# AM335x register map
Vendor: Texas Instruments; Series: Sitara AM335x; File version: 1.1
CPU: Cortex-A8 r0p0, little endian
Registers are 32-bit, read-write, reset 0x0 unless marked. A register's access mark holds for its fields unless they carry their own. Offsets are from the block's base; [hi:lo] are bit positions; {n}, {i} and the like mark numbered series.

## PRM_MPU — Power Reset Module - MPU
Base 0x44E00E00
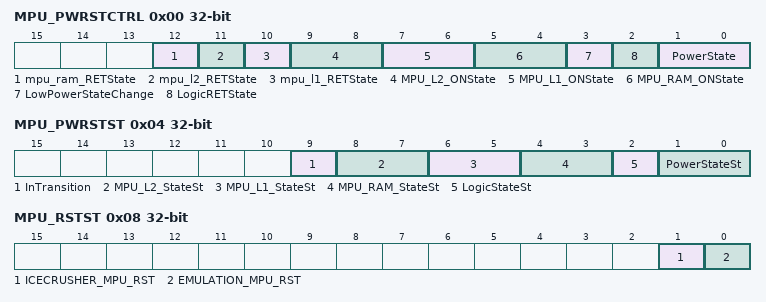
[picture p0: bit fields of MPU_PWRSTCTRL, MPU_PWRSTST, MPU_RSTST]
0x00 MPU_PWRSTCTRL
  [12] mpu_ram_RETState — bit: 24 (RW) Default power domain memory(L2) retention state when power domain is in retention
  [11] mpu_l2_RETState — bit: 23 (RW) Default power domain memory(L1) retention state when power domain is in retention
  [10] mpu_l1_RETState ro — bit: 22 Reserved
  [9:8] MPU_L2_ONState — bit: 20,21 (R) Default power domain memory state when domain is ON.
  [7:6] MPU_L1_ONState — bit: 18,19 (R) Default power domain memory state when domain is ON.
  [5:4] MPU_RAM_ONState — bit: 16,17 (RW) Default power domain memory state when domain is ON [see e_PWR_CTRL_MEM_STATE]
  [3] LowPowerStateChange — bit: 4 (RW) Power state change request when domain has already performed a sleep transition [0x0 = Do not request; 0x1 = Request a low power state change]
  [2] LogicRETState — bit: 2 (RW) Logic state when power domain is RETENTION [0x0 = logic_off; 0x1 = logic_ret]
  [1:0] PowerState — bit: 0,1 (RW) Power state control [see e_PWR_STATE_CTRL]
0x04 MPU_PWRSTST
  [9] InTransition — bit: 20 (R) Domain transition status [0x0 = No on-going transition; 0x1 = transition is in progress.]
  [8:7] MPU_L2_StateSt — bit: 8,9 (R) MPU L2 memory state status [see e_PWR_STATE_MEM_STS]
  [6:5] MPU_L1_StateSt — bit: 6,7 (R) MPU L1 memory state status [see e_PWR_STATE_MEM_STS]
  [4:3] MPU_RAM_StateSt — bit: 5,4 (R) MPU_RAM memory state status [see e_PWR_STATE_MEM_STS]
  [2] LogicStateSt — bit: 2 (R) Logic state status [0x0 = logic_off; 0x1 = logic_on]
  [1:0] PowerStateSt — bit: 0,1 (R) Current Power State Status [see e_PWR_STATE_STS]
0x08 MPU_RSTST
  [1] ICECRUSHER_MPU_RST — bit: 6 (RW) MPU Processor has been reset due to MPU ICECRUSHER1 resetevent [0x0 = RESET_NO; 0x1 = RESET_YES]
  [0] EMULATION_MPU_RST — bit: 5 (RW) MPU Processor has been reset due to emulation reset source e.g. assert reset command initiated by the icepick module [0x0 = RESET_NO; 0x1 = RESET_YES]

## PRM_PER — Power Reset Module - Peripheral
Base 0x44E00C00
0x00 PER_RSTCTRL
  [0] PRU_ICSS_LRST — bit: 1 (RW)PER domain PRU-ICSS local reset control [0x0 = CLEAR; 0x1 = ASSERT]
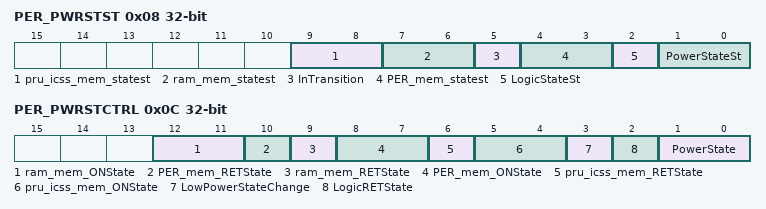
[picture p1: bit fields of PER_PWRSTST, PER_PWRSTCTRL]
0x08 PER_PWRSTST
  [9:8] pru_icss_mem_statest — bit: 23,24 (R)PRU-ICSS memory state status [see e_PWRSTST_MPU]
  [7:6] ram_mem_statest — bit: 21,22 (R)OCMC(on chip memmory controller) RAM memory state status [see e_PWRSTST_MPU]
  [5] InTransition — bit: 20 (R)Domain transition status [0x0 = No on-going transition on power domain; 0x1 = Power domain transition is in progress]
  [4:3] PER_mem_statest — bit: 17,18 (R)PER domain memory state status [see e_PWRSTST_MPU]
  [2] LogicStateSt — bit: 2 (R)Logic state status [0x0 = logic in domain OFF; 0x1 = logic in domain ON]
  [1:0] PowerStateSt — bit: 0,1 (R)Current Power State Status [see e_PWRSTST_MPU]
0x0C PER_PWRSTCTRL
  [12:11] ram_mem_ONState — bit: 30,31 (RW) OCMC(on chip memmory controller) RAM memory on state [see e_PWRSTST_PER]
  [10] PER_mem_RETState — bit: 29 (RW) Other memories in PER Domain RET state [0x0 = off; 0x1 = ret]
  [9] ram_mem_RETState — bit: 27 (RW) OCMC(on chip memmory controller) RAM memory RET state [0x0 = off; 0x1 = ret]
  [8:7] PER_mem_ONState ro — bit: 25,26 (RW) Other memories in PER Domain ON state [0x0..0x2 = Reserved; 0x3 = Memory is ON]
  [6] pru_icss_mem_RETState — bit: 7 (RW) PRU-ICSS memory RET state [0x0 = off; 0x1 = ret]
  [5:4] pru_icss_mem_ONState ro — bit: 5,6 (RW) PRU-ICSS memory ON state [0x0..0x2 = Reserved; 0x3 = Memory is ON]
  [3] LowPowerStateChange — bit: 4 (RW) Power state change request when domain has already performed asleep transition [0x0 = Do not request; 0x1 = Req]
  [2] LogicRETState — bit: 3 (RW) Logic state when power domain is RETENTION [0x0 = logic_off; 0x1 = logic_ret]
  [1:0] PowerState — bit: 0,1 (RW) PER domain power state control [see e_PWRSTST_PER]

## PRM_RTC — Power Reset Module - RTC
Base 0x44E01000
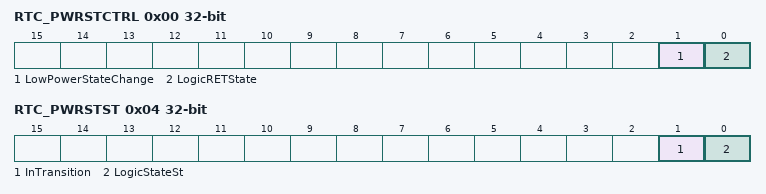
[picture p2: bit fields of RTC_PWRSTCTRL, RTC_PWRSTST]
0x00 RTC_PWRSTCTRL
  [1] LowPowerStateChange — bit: 4 (RW) Power state change request when domain has already performed a sleep transition. [0x0 = Do not request; 0x1 = Request a low power state change]
  [0] LogicRETState — bit: 2 (RW) Logic state when power domain is RETENTION [0x0 = logic_off; 0x1 = logic_on]
0x04 RTC_PWRSTST
  [1] InTransition — bit: 20 (R)Domain transition status [ 0x0 = No on-going transition; 0x1 = transition is in progress.]
  [0] LogicStateSt — bit: 2 (R) Logic state status [0x0 = Logic in domain is OFF; 0x1 = Logic in domain is ON]

## PRM_WKUP — Power Reset Module - Wakeup
Base 0x44E00D00
0x00 WKUP_RSTCTRL
  [0] WKUP_M3_LRST — bit: 3 (RW)Assert Reset to WKUP_M3 [0x0 = CLEAR; 0x1 = ASSERT]
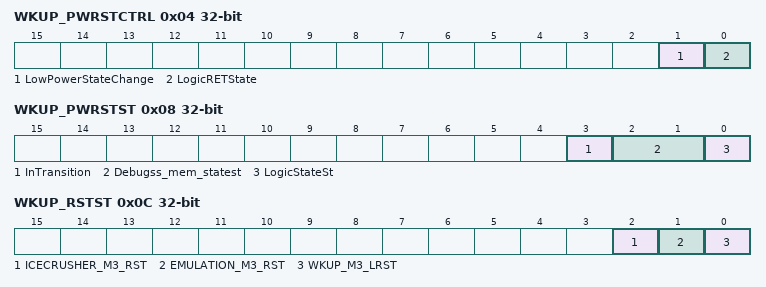
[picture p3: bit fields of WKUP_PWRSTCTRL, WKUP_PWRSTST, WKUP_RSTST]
0x04 WKUP_PWRSTCTRL
  [1] LowPowerStateChange — bit: 4 (RW) Power state change request when domain has already performed a sleep transition [0x0 = Do not request; 0x1 = Request a low power state change]
  [0] LogicRETState — bit: 3 (RW) Logic state when power domain is RETENTION [0x0 = logic off; 0x1 = logic_ret]
0x08 WKUP_PWRSTST
  [3] InTransition — bit: 20 (RW) Domain transition status [0x0 = No on-going transition; 0x1 = Power domain transition is in progress]
  [2:1] Debugss_mem_statest — bit: 17,18 (RW) WKUP domain memory state status [see e_WKUP_DOMAIN_MEM_STATE]
  [0] LogicStateSt — bit: 2 (RW) Logic state status [0x0 = Logic in domain is OFF; 0x1 = Logic in domain is ON]
0x0C WKUP_RSTST
  [2] ICECRUSHER_M3_RST — bit: 7 (RW) M3 Processor has been reset due to M3 ICECRUSHER1 reset event [0x0 = No reset; 0x1 = M3 Processor has been reset]
  [1] EMULATION_M3_RST — bit: 6 (RW) M3 Processor has been reset due to emulation reset source e.g.assert reset command initiated by the icepick module [0x0 = No reset; 0x1 = M3 Processor has been reset]
  [0] WKUP_M3_LRST — bit: 5 (RW) M3 Processor has been reset [0x0 = No reset; 0x1 = M3 Processor has been reset]

## PARAM_00 — PaRAM Set 00
Base 0x49004000
Same registers: PARAM_{n:02} {0x49004000+0x20*n} (n=1..63)
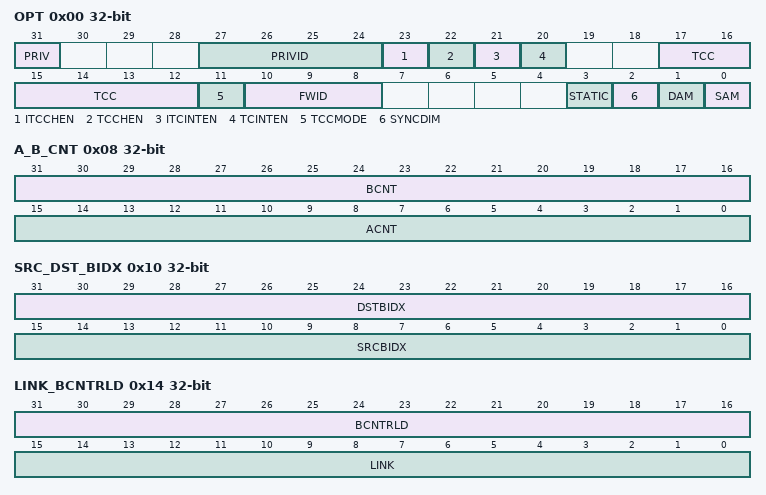
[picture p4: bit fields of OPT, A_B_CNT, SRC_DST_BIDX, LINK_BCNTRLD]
0x00 OPT access not given — Channel Options
  [31] PRIV, [27:24] PRIVID, [23] ITCCHEN, [22] TCCHEN, [21] ITCINTEN, [20] TCINTEN, [17:12] TCC, [11] TCCMODE, [10:8] FWID, [3] STATIC, [2] SYNCDIM, [1] DAM, [0] SAM
0x04 SRC access not given — Source Address
0x08 A_B_CNT access not given — A Count and B Count
  [31:16] BCNT, [15:0] ACNT
0x0C DST access not given — Destination Address
0x10 SRC_DST_BIDX access not given — B-Index (Src/Dst)
  [31:16] DSTBIDX, [15:0] SRCBIDX
0x14 LINK_BCNTRLD access not given — Link Address and B Count Reload
  [31:16] BCNTRLD, [15:0] LINK
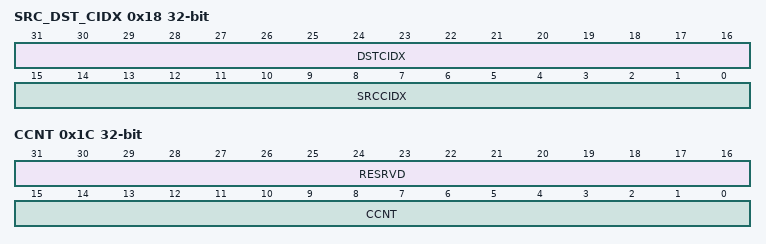
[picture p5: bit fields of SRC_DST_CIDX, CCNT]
0x18 SRC_DST_CIDX access not given — C-Index (Src/Dst)
  [31:16] DSTCIDX, [15:0] SRCCIDX
0x1C CCNT access not given — C Count
  [31:16] RESRVD, [15:0] CCNT
